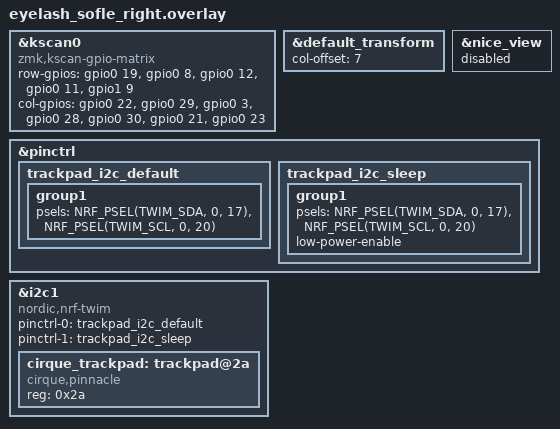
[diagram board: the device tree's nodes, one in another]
/*
*
* Copyright (c) 2021 Darryl deHaan
* SPDX-License-Identifier: MIT
*
*/

#include "eyelash_sofle.dtsi"
#include <behaviors/battery_history_request.dtsi>

&kscan0 {
    compatible = "zmk,kscan-gpio-matrix";
    row-gpios
        = <&gpio0 19 (GPIO_ACTIVE_HIGH | GPIO_PULL_DOWN)>
        , <&gpio0 8 (GPIO_ACTIVE_HIGH | GPIO_PULL_DOWN)>
        , <&gpio0 12 (GPIO_ACTIVE_HIGH | GPIO_PULL_DOWN)>
        , <&gpio0 11 (GPIO_ACTIVE_HIGH | GPIO_PULL_DOWN)>
        , <&gpio1 9 (GPIO_ACTIVE_HIGH | GPIO_PULL_DOWN)>
        ;
    col-gpios
       = <&gpio0 22 GPIO_ACTIVE_HIGH>
        , <&gpio0 29 GPIO_ACTIVE_HIGH>
        , <&gpio0 3 GPIO_ACTIVE_HIGH>
        , <&gpio0 28 GPIO_ACTIVE_HIGH>
        , <&gpio0 30 GPIO_ACTIVE_HIGH>
        , <&gpio0 21 GPIO_ACTIVE_HIGH>
        , <&gpio0 23 GPIO_ACTIVE_HIGH>
        ;
};

&default_transform {
    col-offset = <7>;
};

&nice_view {
    status = "disabled";
};

&pinctrl {
    trackpad_i2c_default: trackpad_i2c_default {
        group1 {
            psels = <NRF_PSEL(TWIM_SDA, 0, 17)>,
                    <NRF_PSEL(TWIM_SCL, 0, 20)>;
        };
    };

    trackpad_i2c_sleep: trackpad_i2c_sleep {
        group1 {
            psels = <NRF_PSEL(TWIM_SDA, 0, 17)>,
                    <NRF_PSEL(TWIM_SCL, 0, 20)>;
            low-power-enable;
        };
    };
};

&i2c1 {
    compatible = "nordic,nrf-twim";
    status = "okay";
    pinctrl-0 = <&trackpad_i2c_default>;
    pinctrl-1 = <&trackpad_i2c_sleep>;
    pinctrl-names = "default", "sleep";

    cirque_trackpad: trackpad@2a {
        compatible = "cirque,pinnacle";
        reg = <0x2a>;
        status = "okay";
    };
};

